# ESP32-C5 register map
Vendor: ESPRESSIF SYSTEMS (SHANGHAI) CO., LTD.; Series: ESP32 C-Series; File version: 1
CPU: RV32IMAC r0p0, little endian, no MPU, no FPU, 0 interrupt priority bits
Address unit: 32 bits
Registers are 32-bit, read-write, reset 0x0 unless marked. A register's access mark holds for its fields unless they carry their own. Offsets are from the block's base; [hi:lo] are bit positions.

## CACHE — Cache controller, preload/sync, and performance counters
Base 0x600C8000
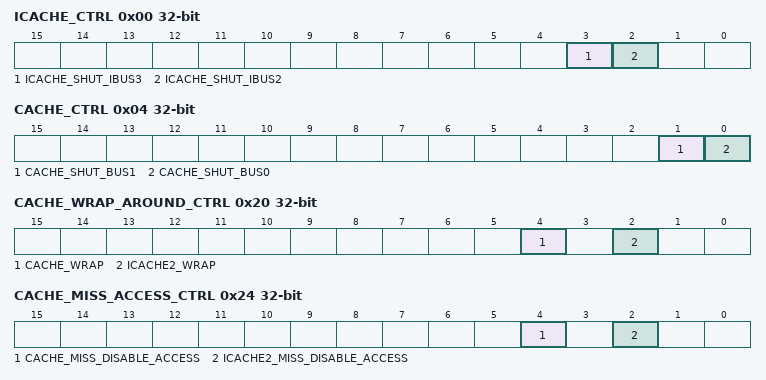
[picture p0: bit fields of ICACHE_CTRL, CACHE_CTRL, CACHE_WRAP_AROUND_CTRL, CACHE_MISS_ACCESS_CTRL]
0x00 ICACHE_CTRL — Instruction cache (ICache) control register
  [3] ICACHE_SHUT_IBUS3 — Reserved
  [2] ICACHE_SHUT_IBUS2 — Reserved
0x04 CACHE_CTRL — Data cache control register
  [1] CACHE_SHUT_BUS1 — The bit is used to disable core0 bus1 access Cache, 0: enable, 1: disable
  [0] CACHE_SHUT_BUS0 — The bit is used to disable core0 bus0 access Cache, 0: enable, 1: disable
0x10 ICACHE_CACHESIZE_CONF ro — Instruction Cache CacheSize mode configure register
  [4] ICACHE_CACHESIZE_4K — The field is used to configure cachesize of ICache as 4k bytes. This field and all other fields within this register is onehot.
0x14 ICACHE_BLOCKSIZE_CONF ro — Instruction Cache BlockSize mode configure register
  [3] ICACHE_BLOCKSIZE_64 — The field is used to configureblocksize of ICache as 64 bytes. This field and all other fields within this register is onehot.
0x18 CACHE_CACHESIZE_CONF ro — Data Cache CacheSize mode configure register
  [7] DCACHE_CACHESIZE_32K — The field is used to configure cachesize of DCache as 32k bytes. This field and all other fields within this register is onehot.
0x1C CACHE_BLOCKSIZE_CONF ro — Data Cache BlockSize mode configure register
  [2] CACHE_BLOCKSIZE_32 — The field is used to configureblocksize of DCache as 32 bytes. This field and all other fields within this register is onehot.
0x20 CACHE_WRAP_AROUND_CTRL — Cache wrap around control register
  [4] CACHE_WRAP — Set this bit as 1 to enable DCache wrap around mode.
  [2] ICACHE2_WRAP — Reserved
0x24 CACHE_MISS_ACCESS_CTRL — Cache wrap around control register
  [4] CACHE_MISS_DISABLE_ACCESS — Set this bit as 1 to disable early restart of DCache
  [2] ICACHE2_MISS_DISABLE_ACCESS — Reserved
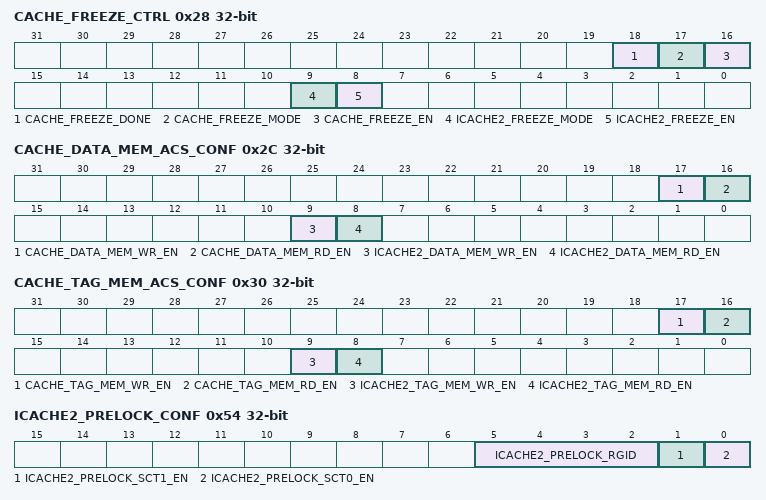
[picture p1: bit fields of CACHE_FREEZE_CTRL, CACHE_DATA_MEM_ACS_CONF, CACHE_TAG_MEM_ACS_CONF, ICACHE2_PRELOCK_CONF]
0x28 CACHE_FREEZE_CTRL — Cache Freeze control register
  [18] CACHE_FREEZE_DONE ro — The bit is used to indicate whether freeze operation on Cache is finished or not. 0: not finished. 1: finished.
  [17] CACHE_FREEZE_MODE — The bit is used to configure mode of freeze operation Cache. 0: a miss-access will not stuck. 1: a miss-access will stuck.
  [16] CACHE_FREEZE_EN — The bit is used to enable freeze operation on Cache. It can be cleared by software.
  [9] ICACHE2_FREEZE_MODE — Reserved
  [8] ICACHE2_FREEZE_EN — Reserved
0x2C CACHE_DATA_MEM_ACS_CONF — Cache data memory access configure register
  [17] CACHE_DATA_MEM_WR_EN — The bit is used to enable config-bus write Cache data memoryory. 0: disable, 1: enable.
  [16] CACHE_DATA_MEM_RD_EN — The bit is used to enable config-bus read Cache data memoryory. 0: disable, 1: enable.
  [9] ICACHE2_DATA_MEM_WR_EN — Reserved
  [8] ICACHE2_DATA_MEM_RD_EN — Reserved
0x30 CACHE_TAG_MEM_ACS_CONF — Cache tag memory access configure register
  [17] CACHE_TAG_MEM_WR_EN — The bit is used to enable config-bus write Cache tag memoryory. 0: disable, 1: enable.
  [16] CACHE_TAG_MEM_RD_EN — The bit is used to enable config-bus read Cache tag memoryory. 0: disable, 1: enable.
  [9] ICACHE2_TAG_MEM_WR_EN — Reserved
  [8] ICACHE2_TAG_MEM_RD_EN — Reserved
0x54 ICACHE2_PRELOCK_CONF — Instruction Cache 2 prelock configure register
  [5:2] ICACHE2_PRELOCK_RGID — The bit is used to set the gid of icache2 prelock.
  [1] ICACHE2_PRELOCK_SCT1_EN — The bit is used to enable the second section of prelock function on ICache2.
  [0] ICACHE2_PRELOCK_SCT0_EN — The bit is used to enable the first section of prelock function on ICache2.
0x58 ICACHE2_PRELOCK_SCT0_ADDR — Instruction Cache 2 prelock section0 address configure register
  [31:0] ICACHE2_PRELOCK_SCT0_ADDR — Those bits are used to configure the start address of the first section of prelock on ICache2, which should be used together with ICACHE2_PRELOCK_SCT0_SIZE_REG
0x5C ICACHE2_PRELOCK_SCT1_ADDR — Instruction Cache 2 prelock section1 address configure register
  [31:0] ICACHE2_PRELOCK_SCT1_ADDR — Those bits are used to configure the start address of the second section of prelock on ICache2, which should be used together with ICACHE2_PRELOCK_SCT1_SIZE_REG
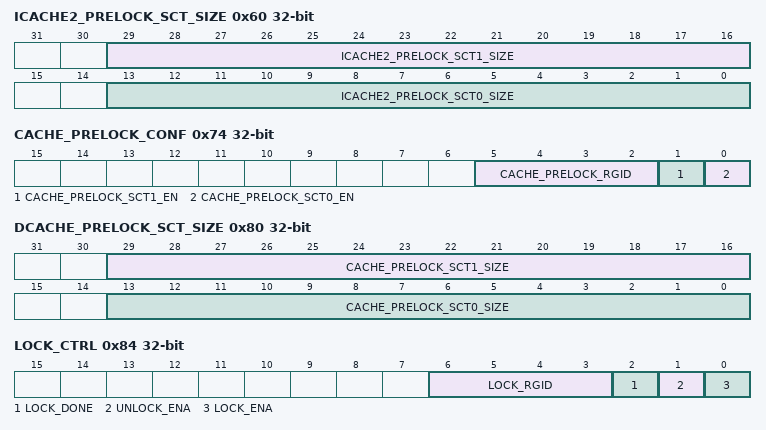
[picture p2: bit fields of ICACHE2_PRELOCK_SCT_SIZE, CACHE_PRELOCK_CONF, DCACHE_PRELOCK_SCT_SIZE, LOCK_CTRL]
0x60 ICACHE2_PRELOCK_SCT_SIZE — Instruction Cache 2 prelock section size configure register
  [29:16] ICACHE2_PRELOCK_SCT1_SIZE — Those bits are used to configure the size of the second section of prelock on ICache2, which should be used together with ICACHE2_PRELOCK_SCT1_ADDR_REG
  [13:0] ICACHE2_PRELOCK_SCT0_SIZE — Those bits are used to configure the size of the first section of prelock on ICache2, which should be used together with ICACHE2_PRELOCK_SCT0_ADDR_REG
0x74 CACHE_PRELOCK_CONF — Cache prelock configure register
  [5:2] CACHE_PRELOCK_RGID ro — The bit is used to set the gid of cache prelock.
  [1] CACHE_PRELOCK_SCT1_EN — The bit is used to enable the second section of prelock function on Cache.
  [0] CACHE_PRELOCK_SCT0_EN — The bit is used to enable the first section of prelock function on Cache.
0x78 CACHE_PRELOCK_SCT0_ADDR — Cache prelock section0 address configure register
  [31:0] CACHE_PRELOCK_SCT0_ADDR — Those bits are used to configure the start address of the first section of prelock on Cache, which should be used together with CACHE_PRELOCK_SCT0_SIZE_REG
0x7C DCACHE_PRELOCK_SCT1_ADDR — Cache prelock section1 address configure register
  [31:0] CACHE_PRELOCK_SCT1_ADDR — Those bits are used to configure the start address of the second section of prelock on Cache, which should be used together with CACHE_PRELOCK_SCT1_SIZE_REG
0x80 DCACHE_PRELOCK_SCT_SIZE — Cache prelock section size configure register
  [29:16] CACHE_PRELOCK_SCT1_SIZE — Those bits are used to configure the size of the second section of prelock on Cache, which should be used together with CACHE_PRELOCK_SCT1_ADDR_REG
  [13:0] CACHE_PRELOCK_SCT0_SIZE — Those bits are used to configure the size of the first section of prelock on Cache, which should be used together with CACHE_PRELOCK_SCT0_ADDR_REG
0x84 LOCK_CTRL — Lock-class (manual lock) operation control register
  [6:3] LOCK_RGID ro — The bit is used to set the gid of cache lock/unlock.
  [2] LOCK_DONE ro — The bit is used to indicate whether unlock/lock operation is finished or not. 0: not finished. 1: finished.
  [1] UNLOCK_ENA — The bit is used to enable unlock operation. It will be cleared by hardware after unlock operation done
  [0] LOCK_ENA — The bit is used to enable lock operation. It will be cleared by hardware after lock operation done
0x88 LOCK_MAP — Lock (manual lock) map configure register
  [5:0] LOCK_MAP — Those bits are used to indicate which caches in the two-level cache structure will apply this lock/unlock operation. [4]: Cache
0x8C LOCK_ADDR — Lock (manual lock) address configure register
  [31:0] LOCK_ADDR — Those bits are used to configure the start address of the lock/unlock operation, which should be used together with CACHE_LOCK_SIZE_REG
0x90 LOCK_SIZE — Lock (manual lock) size configure register
  [15:0] LOCK_SIZE — Those bits are used to configure the size of the lock/unlock operation, which should be used together with CACHE_LOCK_ADDR_REG
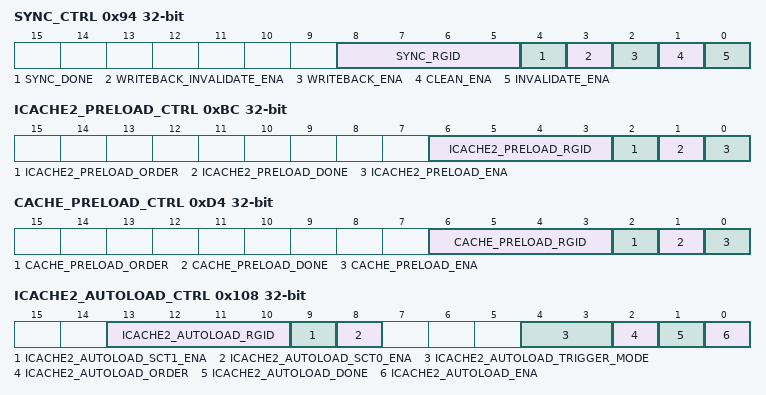
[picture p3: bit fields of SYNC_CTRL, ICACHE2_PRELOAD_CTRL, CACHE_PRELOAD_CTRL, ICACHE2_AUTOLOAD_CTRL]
0x94 SYNC_CTRL — Sync-class operation control register
  [8:5] SYNC_RGID ro — The bit is used to set the gid of cache sync operation (invalidate, clean, writeback, writeback_invalidate)
  [4] SYNC_DONE ro — The bit is used to indicate whether sync operation (invalidate, clean, writeback, writeback_invalidate) is finished or not. 0: not finished. 1: finished.
  [3] WRITEBACK_INVALIDATE_ENA — The bit is used to enable writeback-invalidate operation. It will be cleared by hardware after writeback-invalidate operation done. Note that this bit and the other sync-bits (invalidate_ena, clean_ena, writeback_ena) are mutually exclusive, that is, those bits can not be set to 1 at the same time.
  [2] WRITEBACK_ENA — The bit is used to enable writeback operation. It will be cleared by hardware after writeback operation done. Note that this bit and the other sync-bits (invalidate_ena, clean_ena, writeback_invalidate_ena) are mutually exclusive, that is, those bits can not be set to 1 at the same time.
  [1] CLEAN_ENA — The bit is used to enable clean operation. It will be cleared by hardware after clean operation done. Note that this bit and the other sync-bits (invalidate_ena, writeback_ena, writeback_invalidate_ena) are mutually exclusive, that is, those bits can not be set to 1 at the same time.
  [0] INVALIDATE_ENA — The bit is used to enable invalidate operation. It will be cleared by hardware after invalidate operation done. Note that this bit and the other sync-bits (clean_ena, writeback_ena, writeback_invalidate_ena) are mutually exclusive, that is, those bits can not be set to 1 at the same time.
0x98 SYNC_MAP — Sync map configure register
  [5:0] SYNC_MAP — Those bits are used to indicate which caches in the two-level cache structure will apply the sync operation. [4]: Cache
0x9C SYNC_ADDR — Sync address configure register
  [31:0] SYNC_ADDR — Those bits are used to configure the start address of the sync operation, which should be used together with CACHE_SYNC_SIZE_REG
0xA0 SYNC_SIZE — Sync size configure register
  [24:0] SYNC_SIZE — Those bits are used to configure the size of the sync operation, which should be used together with CACHE_SYNC_ADDR_REG
0xBC ICACHE2_PRELOAD_CTRL — Instruction Cache 2 preload-operation control register
  [6:3] ICACHE2_PRELOAD_RGID — The bit is used to set the gid of icache2 preload.
  [2] ICACHE2_PRELOAD_ORDER — The bit is used to configure the direction of preload operation. 0: ascending, 1: descending.
  [1] ICACHE2_PRELOAD_DONE ro — The bit is used to indicate whether preload operation is finished or not. 0: not finished. 1: finished.
  [0] ICACHE2_PRELOAD_ENA — The bit is used to enable preload operation on ICache2. It will be cleared by hardware automatically after preload operation is done.
0xC0 ICACHE2_PRELOAD_ADDR — Instruction Cache 2 preload address configure register
  [31:0] ICACHE2_PRELOAD_ADDR — Those bits are used to configure the start address of preload on ICache2, which should be used together with ICACHE2_PRELOAD_SIZE_REG
0xC4 ICACHE2_PRELOAD_SIZE — Instruction Cache 2 preload size configure register
  [13:0] ICACHE2_PRELOAD_SIZE — Those bits are used to configure the size of the first section of prelock on ICache2, which should be used together with ICACHE2_PRELOAD_ADDR_REG
0xD4 CACHE_PRELOAD_CTRL — Cache preload-operation control register
  [6:3] CACHE_PRELOAD_RGID ro — The bit is used to set the gid of cache preload.
  [2] CACHE_PRELOAD_ORDER — The bit is used to configure the direction of preload operation. 0: ascending, 1: descending.
  [1] CACHE_PRELOAD_DONE ro — The bit is used to indicate whether preload operation is finished or not. 0: not finished. 1: finished.
  [0] CACHE_PRELOAD_ENA — The bit is used to enable preload operation on Cache. It will be cleared by hardware automatically after preload operation is done.
0xD8 DCACHE_PRELOAD_ADDR — Cache preload address configure register
  [31:0] CACHE_PRELOAD_ADDR — Those bits are used to configure the start address of preload on Cache, which should be used together with CACHE_PRELOAD_SIZE_REG
0xDC DCACHE_PRELOAD_SIZE — Cache preload size configure register
  [13:0] CACHE_PRELOAD_SIZE — Those bits are used to configure the size of the first section of prelock on Cache, which should be used together with CACHE_PRELOAD_ADDR_REG
0x108 ICACHE2_AUTOLOAD_CTRL — Instruction Cache 2 autoload-operation control register
  [13:10] ICACHE2_AUTOLOAD_RGID — The bit is used to set the gid of icache2 autoload.
  [9] ICACHE2_AUTOLOAD_SCT1_ENA — The bit is used to enable the second section for autoload operation on ICache2.
  [8] ICACHE2_AUTOLOAD_SCT0_ENA — The bit is used to enable the first section for autoload operation on ICache2.
  [4:3] ICACHE2_AUTOLOAD_TRIGGER_MODE — The field is used to configure trigger mode of autoload operation on ICache2. 0/3: miss-trigger, 1: hit-trigger, 2: miss-hit-trigger.
  [2] ICACHE2_AUTOLOAD_ORDER — The bit is used to configure the direction of autoload operation on ICache2. 0: ascending. 1: descending.
  [1] ICACHE2_AUTOLOAD_DONE ro — The bit is used to indicate whether autoload operation on ICache2 is finished or not. 0: not finished. 1: finished.
  [0] ICACHE2_AUTOLOAD_ENA — The bit is used to enable and disable autoload operation on ICache2. 1: enable, 0: disable.
0x10C ICACHE2_AUTOLOAD_SCT0_ADDR — Instruction Cache 2 autoload section 0 address configure register
  [31:0] ICACHE2_AUTOLOAD_SCT0_ADDR — Those bits are used to configure the start address of the first section for autoload operation on ICache2. Note that it should be used together with ICACHE2_AUTOLOAD_SCT0_SIZE and ICACHE_AUTOLOAD_SCT0_ENA.
0x110 ICACHE2_AUTOLOAD_SCT0_SIZE — Instruction Cache 2 autoload section 0 size configure register
  [27:0] ICACHE2_AUTOLOAD_SCT0_SIZE — Those bits are used to configure the size of the first section for autoload operation on ICache2. Note that it should be used together with ICACHE2_AUTOLOAD_SCT0_ADDR and ICACHE_AUTOLOAD_SCT0_ENA.
0x114 ICACHE2_AUTOLOAD_SCT1_ADDR — Instruction Cache 2 autoload section 1 address configure register
  [31:0] ICACHE2_AUTOLOAD_SCT1_ADDR — Those bits are used to configure the start address of the second section for autoload operation on ICache2. Note that it should be used together with ICACHE2_AUTOLOAD_SCT1_SIZE and ICACHE_AUTOLOAD_SCT1_ENA.
0x118 ICACHE2_AUTOLOAD_SCT1_SIZE — Instruction Cache 2 autoload section 1 size configure register
  [27:0] ICACHE2_AUTOLOAD_SCT1_SIZE — Those bits are used to configure the size of the second section for autoload operation on ICache2. Note that it should be used together with ICACHE2_AUTOLOAD_SCT1_ADDR and ICACHE_AUTOLOAD_SCT1_ENA.
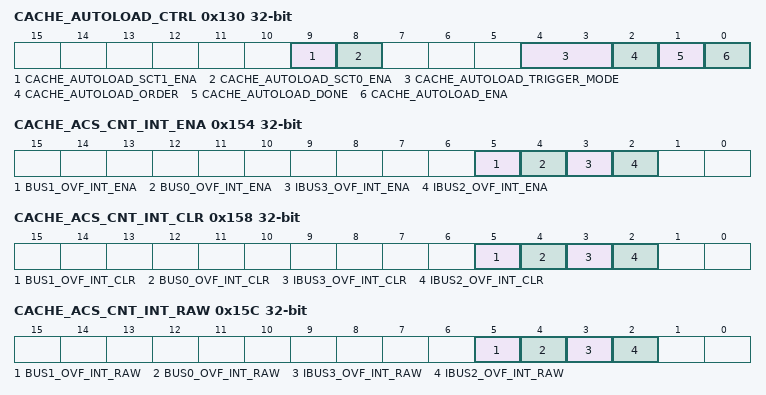
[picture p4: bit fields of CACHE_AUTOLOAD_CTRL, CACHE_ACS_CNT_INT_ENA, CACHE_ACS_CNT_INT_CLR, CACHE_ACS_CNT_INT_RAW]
0x130 CACHE_AUTOLOAD_CTRL — Cache autoload-operation control register
  [9] CACHE_AUTOLOAD_SCT1_ENA — The bit is used to enable the second section for autoload operation on Cache.
  [8] CACHE_AUTOLOAD_SCT0_ENA — The bit is used to enable the first section for autoload operation on Cache.
  [4:3] CACHE_AUTOLOAD_TRIGGER_MODE — The field is used to configure trigger mode of autoload operation on Cache. 0/3: miss-trigger, 1: hit-trigger, 2: miss-hit-trigger.
  [2] CACHE_AUTOLOAD_ORDER — The bit is used to configure the direction of autoload operation on Cache. 0: ascending. 1: descending.
  [1] CACHE_AUTOLOAD_DONE ro — The bit is used to indicate whether autoload operation on Cache is finished or not. 0: not finished. 1: finished.
  [0] CACHE_AUTOLOAD_ENA — The bit is used to enable and disable autoload operation on Cache. 1: enable, 0: disable.
0x134 CACHE_AUTOLOAD_SCT0_ADDR — Cache autoload section 0 address configure register
  [31:0] CACHE_AUTOLOAD_SCT0_ADDR — Those bits are used to configure the start address of the first section for autoload operation on Cache. Note that it should be used together with CACHE_AUTOLOAD_SCT0_SIZE and CACHE_AUTOLOAD_SCT0_ENA.
0x138 CACHE_AUTOLOAD_SCT0_SIZE — Cache autoload section 0 size configure register
  [24:0] CACHE_AUTOLOAD_SCT0_SIZE — Those bits are used to configure the size of the first section for autoload operation on Cache. Note that it should be used together with CACHE_AUTOLOAD_SCT0_ADDR and CACHE_AUTOLOAD_SCT0_ENA.
0x13C CACHE_AUTOLOAD_SCT1_ADDR — Cache autoload section 1 address configure register
  [31:0] CACHE_AUTOLOAD_SCT1_ADDR — Those bits are used to configure the start address of the second section for autoload operation on Cache. Note that it should be used together with CACHE_AUTOLOAD_SCT1_SIZE and CACHE_AUTOLOAD_SCT1_ENA.
0x140 CACHE_AUTOLOAD_SCT1_SIZE — Cache autoload section 1 size configure register
  [24:0] CACHE_AUTOLOAD_SCT1_SIZE — Those bits are used to configure the size of the second section for autoload operation on Cache. Note that it should be used together with CACHE_AUTOLOAD_SCT1_ADDR and CACHE_AUTOLOAD_SCT1_ENA.
0x154 CACHE_ACS_CNT_INT_ENA — Cache Access Counter Interrupt enable register
  [5] BUS1_OVF_INT_ENA — The bit is used to enable interrupt of one of counters overflow that occurs in DCache due to bus1 accesses DCache.
  [4] BUS0_OVF_INT_ENA — The bit is used to enable interrupt of one of counters overflow that occurs in DCache due to bus0 accesses DCache.
  [3] IBUS3_OVF_INT_ENA — Reserved
  [2] IBUS2_OVF_INT_ENA — Reserved
0x158 CACHE_ACS_CNT_INT_CLR wo — Cache Access Counter Interrupt clear register
  [5] BUS1_OVF_INT_CLR — The bit is used to clear counters overflow interrupt and counters in DCache due to bus1 accesses DCache.
  [4] BUS0_OVF_INT_CLR — The bit is used to clear counters overflow interrupt and counters in DCache due to bus0 accesses DCache.
  [3] IBUS3_OVF_INT_CLR — Reserved
  [2] IBUS2_OVF_INT_CLR — Reserved
0x15C CACHE_ACS_CNT_INT_RAW — Cache Access Counter Interrupt raw register
  [5] BUS1_OVF_INT_RAW — The raw bit of the interrupt of one of counters overflow that occurs in DCache due to bus1 accesses DCache.
  [4] BUS0_OVF_INT_RAW — The raw bit of the interrupt of one of counters overflow that occurs in DCache due to bus0 accesses DCache.
  [3] IBUS3_OVF_INT_RAW — The raw bit of the interrupt of one of counters overflow that occurs in ICache3 due to bus3 accesses ICache3.
  [2] IBUS2_OVF_INT_RAW — The raw bit of the interrupt of one of counters overflow that occurs in ICache2 due to bus2 accesses ICache2.
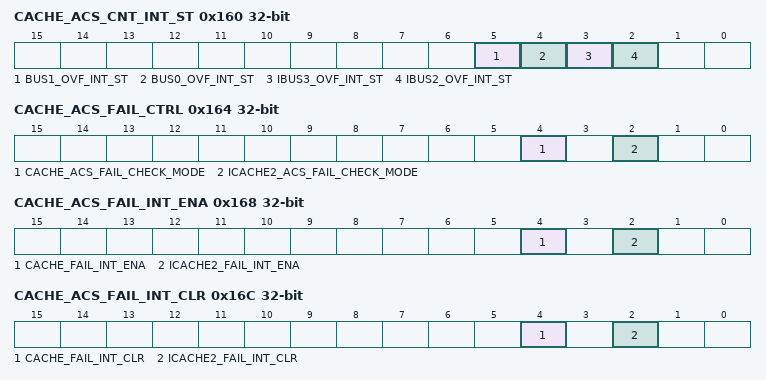
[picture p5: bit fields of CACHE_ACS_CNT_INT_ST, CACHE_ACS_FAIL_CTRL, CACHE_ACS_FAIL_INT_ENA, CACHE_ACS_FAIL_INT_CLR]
0x160 CACHE_ACS_CNT_INT_ST ro — Cache Access Counter Interrupt status register
  [5] BUS1_OVF_INT_ST — The bit indicates the interrupt status of one of counters overflow that occurs in DCache due to bus1 accesses DCache.
  [4] BUS0_OVF_INT_ST — The bit indicates the interrupt status of one of counters overflow that occurs in DCache due to bus0 accesses DCache.
  [3] IBUS3_OVF_INT_ST — Reserved
  [2] IBUS2_OVF_INT_ST — Reserved
0x164 CACHE_ACS_FAIL_CTRL — Cache Access Fail Configuration register
  [4] CACHE_ACS_FAIL_CHECK_MODE — The bit is used to configure cache access fail check mode. 0: the access fail is not propagated to the request, 1: the access fail is propagated to the request
  [2] ICACHE2_ACS_FAIL_CHECK_MODE — The bit is used to configure icache2 access fail check mode. 0: the access fail is not propagated to the request, 1: the access fail is propagated to the request
0x168 CACHE_ACS_FAIL_INT_ENA — Cache Access Fail Interrupt enable register
  [4] CACHE_FAIL_INT_ENA — The bit is used to enable interrupt of access fail that occurs in DCache due to cpu accesses DCache.
  [2] ICACHE2_FAIL_INT_ENA — Reserved
0x16C CACHE_ACS_FAIL_INT_CLR wo — Cache Access Fail Interrupt clear register
  [4] CACHE_FAIL_INT_CLR — The bit is used to clear interrupt of access fail that occurs in DCache due to cpu accesses DCache.
  [2] ICACHE2_FAIL_INT_CLR — Reserved
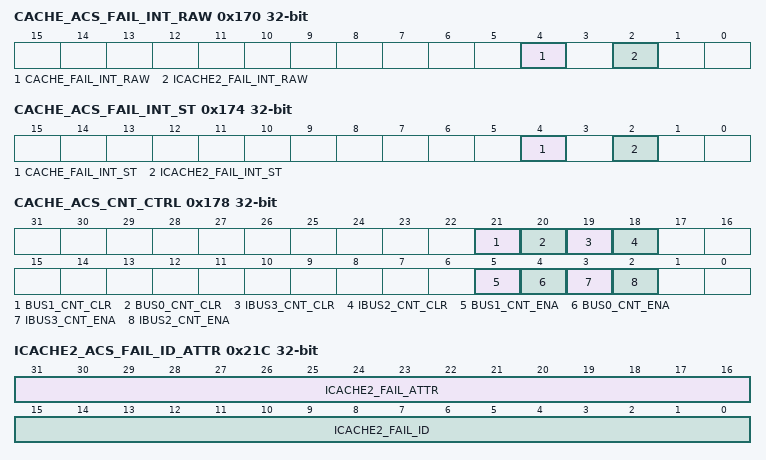
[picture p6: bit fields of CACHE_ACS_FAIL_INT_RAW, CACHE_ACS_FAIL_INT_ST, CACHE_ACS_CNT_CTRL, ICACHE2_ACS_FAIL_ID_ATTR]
0x170 CACHE_ACS_FAIL_INT_RAW — Cache Access Fail Interrupt raw register
  [4] CACHE_FAIL_INT_RAW — The raw bit of the interrupt of access fail that occurs in DCache.
  [2] ICACHE2_FAIL_INT_RAW — The raw bit of the interrupt of access fail that occurs in ICache2.
0x174 CACHE_ACS_FAIL_INT_ST ro — Cache Access Fail Interrupt status register
  [4] CACHE_FAIL_INT_ST — The bit indicates the interrupt status of access fail that occurs in DCache due to cpu accesses DCache.
  [2] ICACHE2_FAIL_INT_ST — Reserved
0x178 CACHE_ACS_CNT_CTRL — Cache Access Counter enable and clear register
  [21] BUS1_CNT_CLR wo — The bit is used to clear dbus1 counter in DCache.
  [20] BUS0_CNT_CLR wo — The bit is used to clear dbus0 counter in DCache.
  [19] IBUS3_CNT_CLR wo — Reserved
  [18] IBUS2_CNT_CLR wo — Reserved
  [5] BUS1_CNT_ENA — The bit is used to enable dbus1 counter in DCache.
  [4] BUS0_CNT_ENA — The bit is used to enable dbus0 counter in DCache.
  [3] IBUS3_CNT_ENA — Reserved
  [2] IBUS2_CNT_ENA — Reserved
0x19C IBUS2_ACS_HIT_CNT ro — ICache bus2 Hit-Access Counter register
  [31:0] IBUS2_HIT_CNT — The register records the number of hits when bus2 accesses ICache2.
0x1A0 IBUS2_ACS_MISS_CNT ro — ICache bus2 Miss-Access Counter register
  [31:0] IBUS2_MISS_CNT — The register records the number of missing when bus2 accesses ICache2.
0x1A4 IBUS2_ACS_CONFLICT_CNT ro — ICache bus2 Conflict-Access Counter register
  [31:0] IBUS2_CONFLICT_CNT — The register records the number of access-conflicts when bus2 accesses ICache2.
0x1A8 IBUS2_ACS_NXTLVL_RD_CNT ro — ICache bus2 Next-Level-Access Counter register
  [31:0] IBUS2_NXTLVL_RD_CNT — The register records the number of times that ICache accesses L2-Cache due to bus2 accessing ICache2.
0x1AC IBUS3_ACS_HIT_CNT ro — ICache bus3 Hit-Access Counter register
  [31:0] IBUS3_HIT_CNT — The register records the number of hits when bus3 accesses ICache3.
0x1B0 IBUS3_ACS_MISS_CNT ro — ICache bus3 Miss-Access Counter register
  [31:0] IBUS3_MISS_CNT — The register records the number of missing when bus3 accesses ICache3.
0x1B4 IBUS3_ACS_CONFLICT_CNT ro — ICache bus3 Conflict-Access Counter register
  [31:0] IBUS3_CONFLICT_CNT — The register records the number of access-conflicts when bus3 accesses ICache3.
0x1B8 IBUS3_ACS_NXTLVL_RD_CNT ro — ICache bus3 Next-Level-Access Counter register
  [31:0] IBUS3_NXTLVL_RD_CNT — The register records the number of times that ICache accesses L2-Cache due to bus3 accessing ICache3.
0x1BC BUS0_ACS_HIT_CNT ro — Cache bus0 Hit-Access Counter register
  [31:0] BUS0_HIT_CNT — The register records the number of hits when bus0 accesses Cache.
0x1C0 BUS0_ACS_MISS_CNT ro — Cache bus0 Miss-Access Counter register
  [31:0] BUS0_MISS_CNT — The register records the number of missing when bus0 accesses Cache.
0x1C4 BUS0_ACS_CONFLICT_CNT ro — Cache bus0 Conflict-Access Counter register
  [31:0] BUS0_CONFLICT_RD_CNT — The register records the number of access-conflicts when bus0 accesses Cache.
0x1C8 DBUS0_ACS_NXTLVL_RD_CNT ro — Cache bus0 Next-Level-Access Counter register
  [31:0] BUS0_NXTLVL_RD_CNT — The register records the number of times that Cache accesses L2-Cache due to bus0 accessing Cache.
0x1CC DBUS0_ACS_NXTLVL_WR_CNT ro — DCache bus0 WB-Access Counter register
  [31:0] BUS0_NXTLVL_WR_CNT — The register records the number of write back when bus0 accesses Cache.
0x1D0 BUS1_ACS_HIT_CNT ro — Cache bus1 Hit-Access Counter register
  [31:0] BUS1_HIT_CNT — The register records the number of hits when bus1 accesses Cache.
0x1D4 BUS1_ACS_MISS_CNT ro — Cache bus1 Miss-Access Counter register
  [31:0] BUS1_MISS_CNT — The register records the number of missing when bus1 accesses Cache.
0x1D8 BUS1_ACS_CONFLICT_CNT ro — Cache bus1 Conflict-Access Counter register
  [31:0] BUS1_CONFLICT_CNT — The register records the number of access-conflicts when bus1 accesses Cache.
0x1DC DBUS1_ACS_NXTLVL_RD_CNT ro — DCache bus1 Next-Level-Access Counter register
  [31:0] DBUS1_NXTLVL_RD_CNT — The register records the number of times that Cache accesses L2-Cache due to bus1 accessing Cache.
0x1E0 DBUS1_ACS_NXTLVL_WR_CNT ro — DCache bus1 WB-Access Counter register
  [31:0] DBUS1_NXTLVL_WR_CNT — The register records the number of write back when bus1 accesses Cache.
0x21C ICACHE2_ACS_FAIL_ID_ATTR ro — ICache0 Access Fail ID/attribution information register
  [31:16] ICACHE2_FAIL_ATTR — The register records the attribution of fail-access when cache2 accesses ICache.
  [15:0] ICACHE2_FAIL_ID — The register records the ID of fail-access when cache2 accesses ICache.
0x220 ICACHE2_ACS_FAIL_ADDR ro — ICache0 Access Fail Address information register
  [31:0] ICACHE2_FAIL_ADDR — The register records the address of fail-access when cache2 accesses ICache.
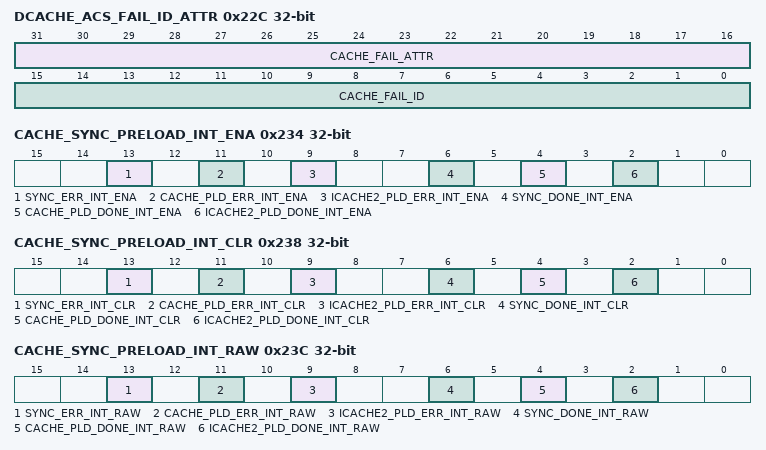
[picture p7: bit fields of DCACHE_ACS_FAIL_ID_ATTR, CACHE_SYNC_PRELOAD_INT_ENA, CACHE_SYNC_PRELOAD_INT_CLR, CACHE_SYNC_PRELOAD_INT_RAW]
0x22C DCACHE_ACS_FAIL_ID_ATTR ro — Cache Access Fail ID/attribution information register
  [31:16] CACHE_FAIL_ATTR — The register records the attribution of fail-access when cache accesses Cache.
  [15:0] CACHE_FAIL_ID — The register records the ID of fail-access when cache accesses Cache.
0x230 DCACHE_ACS_FAIL_ADDR ro — Cache Access Fail Address information register
  [31:0] CACHE_FAIL_ADDR — The register records the address of fail-access when cache accesses Cache.
0x234 CACHE_SYNC_PRELOAD_INT_ENA — Cache Access Fail Interrupt enable register
  [13] SYNC_ERR_INT_ENA — The bit is used to enable interrupt of Cache sync-operation error.
  [11] CACHE_PLD_ERR_INT_ENA — The bit is used to enable interrupt of Cache preload-operation error.
  [9] ICACHE2_PLD_ERR_INT_ENA — Reserved
  [6] SYNC_DONE_INT_ENA — The bit is used to enable interrupt of Cache sync-operation done.
  [4] CACHE_PLD_DONE_INT_ENA — The bit is used to enable interrupt of Cache preload-operation. If preload operation is done, interrupt occurs.
  [2] ICACHE2_PLD_DONE_INT_ENA — Reserved
0x238 CACHE_SYNC_PRELOAD_INT_CLR wo — Sync Preload operation Interrupt clear register
  [13] SYNC_ERR_INT_CLR — The bit is used to clear interrupt of Cache sync-operation error.
  [11] CACHE_PLD_ERR_INT_CLR — The bit is used to clear interrupt of Cache preload-operation error.
  [9] ICACHE2_PLD_ERR_INT_CLR — Reserved
  [6] SYNC_DONE_INT_CLR — The bit is used to clear interrupt that occurs only when Cache sync-operation is done.
  [4] CACHE_PLD_DONE_INT_CLR — The bit is used to clear interrupt that occurs only when Cache preload-operation is done.
  [2] ICACHE2_PLD_DONE_INT_CLR — Reserved
0x23C CACHE_SYNC_PRELOAD_INT_RAW — Sync Preload operation Interrupt raw register
  [13] SYNC_ERR_INT_RAW — The raw bit of the interrupt that occurs only when Cache sync-operation error occurs.
  [11] CACHE_PLD_ERR_INT_RAW — The raw bit of the interrupt that occurs only when Cache preload-operation error occurs.
  [9] ICACHE2_PLD_ERR_INT_RAW — Reserved
  [6] SYNC_DONE_INT_RAW — The raw bit of the interrupt that occurs only when Cache sync-operation is done.
  [4] CACHE_PLD_DONE_INT_RAW — The raw bit of the interrupt that occurs only when Cache preload-operation is done.
  [2] ICACHE2_PLD_DONE_INT_RAW — Reserved
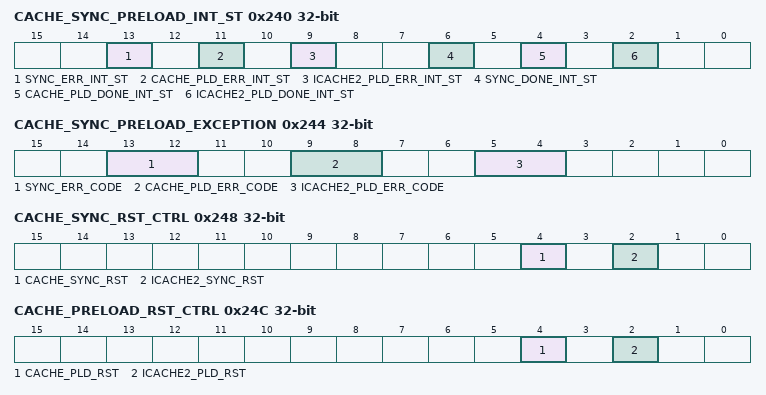
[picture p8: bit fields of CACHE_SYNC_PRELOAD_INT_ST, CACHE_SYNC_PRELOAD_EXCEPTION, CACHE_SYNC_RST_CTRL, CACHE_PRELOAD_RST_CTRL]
0x240 CACHE_SYNC_PRELOAD_INT_ST ro — Cache Access Fail Interrupt status register
  [13] SYNC_ERR_INT_ST — The bit indicates the status of the interrupt of Cache sync-operation error.
  [11] CACHE_PLD_ERR_INT_ST — The bit indicates the status of the interrupt of Cache preload-operation error.
  [9] ICACHE2_PLD_ERR_INT_ST — Reserved
  [6] SYNC_DONE_INT_ST — The bit indicates the status of the interrupt that occurs only when Cache sync-operation is done.
  [4] CACHE_PLD_DONE_INT_ST — The bit indicates the status of the interrupt that occurs only when Cache preload-operation is done.
  [2] ICACHE2_PLD_DONE_INT_ST — Reserved
0x244 CACHE_SYNC_PRELOAD_EXCEPTION ro — Cache Sync/Preload Operation exception register
  [13:12] SYNC_ERR_CODE — The values 0-2 are available which means sync map, command conflict and size are error in Cache System.
  [9:8] CACHE_PLD_ERR_CODE — The value 2 is Only available which means preload size is error in Cache.
  [5:4] ICACHE2_PLD_ERR_CODE — Reserved
0x248 CACHE_SYNC_RST_CTRL — Cache Sync Reset control register
  [4] CACHE_SYNC_RST — set this bit to reset sync-logic inside Cache. Recommend that this should only be used to initialize sync-logic when some fatal error of sync-logic occurs.
  [2] ICACHE2_SYNC_RST — Reserved
0x24C CACHE_PRELOAD_RST_CTRL — Cache Preload Reset control register
  [4] CACHE_PLD_RST — set this bit to reset preload-logic inside Cache. Recommend that this should only be used to initialize preload-logic when some fatal error of preload-logic occurs.
  [2] ICACHE2_PLD_RST — Reserved
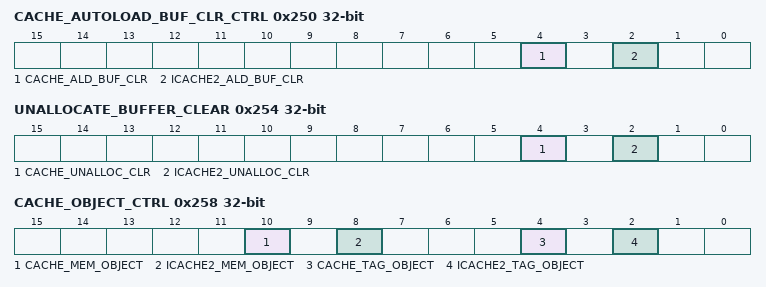
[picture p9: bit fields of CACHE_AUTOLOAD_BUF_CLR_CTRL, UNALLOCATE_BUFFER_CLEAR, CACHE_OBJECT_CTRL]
0x250 CACHE_AUTOLOAD_BUF_CLR_CTRL — Cache Autoload buffer clear control register
  [4] CACHE_ALD_BUF_CLR — set this bit to clear autoload-buffer inside Cache. If this bit is active, autoload will not work in Cache. This bit should not be active when autoload works in Cache.
  [2] ICACHE2_ALD_BUF_CLR — Reserved
0x254 UNALLOCATE_BUFFER_CLEAR — Unallocate request buffer clear registers
  [4] CACHE_UNALLOC_CLR — The bit is used to clear the unallocate request buffer of cache where the unallocate request is responded but not completed.
  [2] ICACHE2_UNALLOC_CLR — Reserved
0x258 CACHE_OBJECT_CTRL — Cache Tag and Data memory Object control register
  [10] CACHE_MEM_OBJECT — Set this bit to set Cache data memory as object. This bit should be onehot with the others fields inside this register.
  [8] ICACHE2_MEM_OBJECT — Reserved
  [4] CACHE_TAG_OBJECT — Set this bit to set Cache tag memory as object. This bit should be onehot with the others fields inside this register.
  [2] ICACHE2_TAG_OBJECT — Reserved
0x25C CACHE_WAY_OBJECT — Cache Tag and Data memory way register
  [2:0] CACHE_WAY_OBJECT — Set this bits to select which way of the tag-object will be accessed. 0: way0, 1: way1, 2: way2, 3: way3, ?, 7: way7.
0x260 CACHE_ADDR — Cache address register
  [31:0] CACHE_ADDR — Those bits stores the address which will decide where inside the specified tag memory object will be accessed.
0x264 CACHE_DEBUG_BUS — Cache Tag/data memory content register
  [31:0] CACHE_DEBUG_BUS — This is a constant place where we can write data to or read data from the tag/data memory on the specified cache.
0x3D0 TRACE_ENA — Clock gate control register
  [0] CACHE_TRACE_ENA — The bit is used to enable Cache trace for the performance counter and fail tracer
0x3FC CACHE_DATE — Version control register
